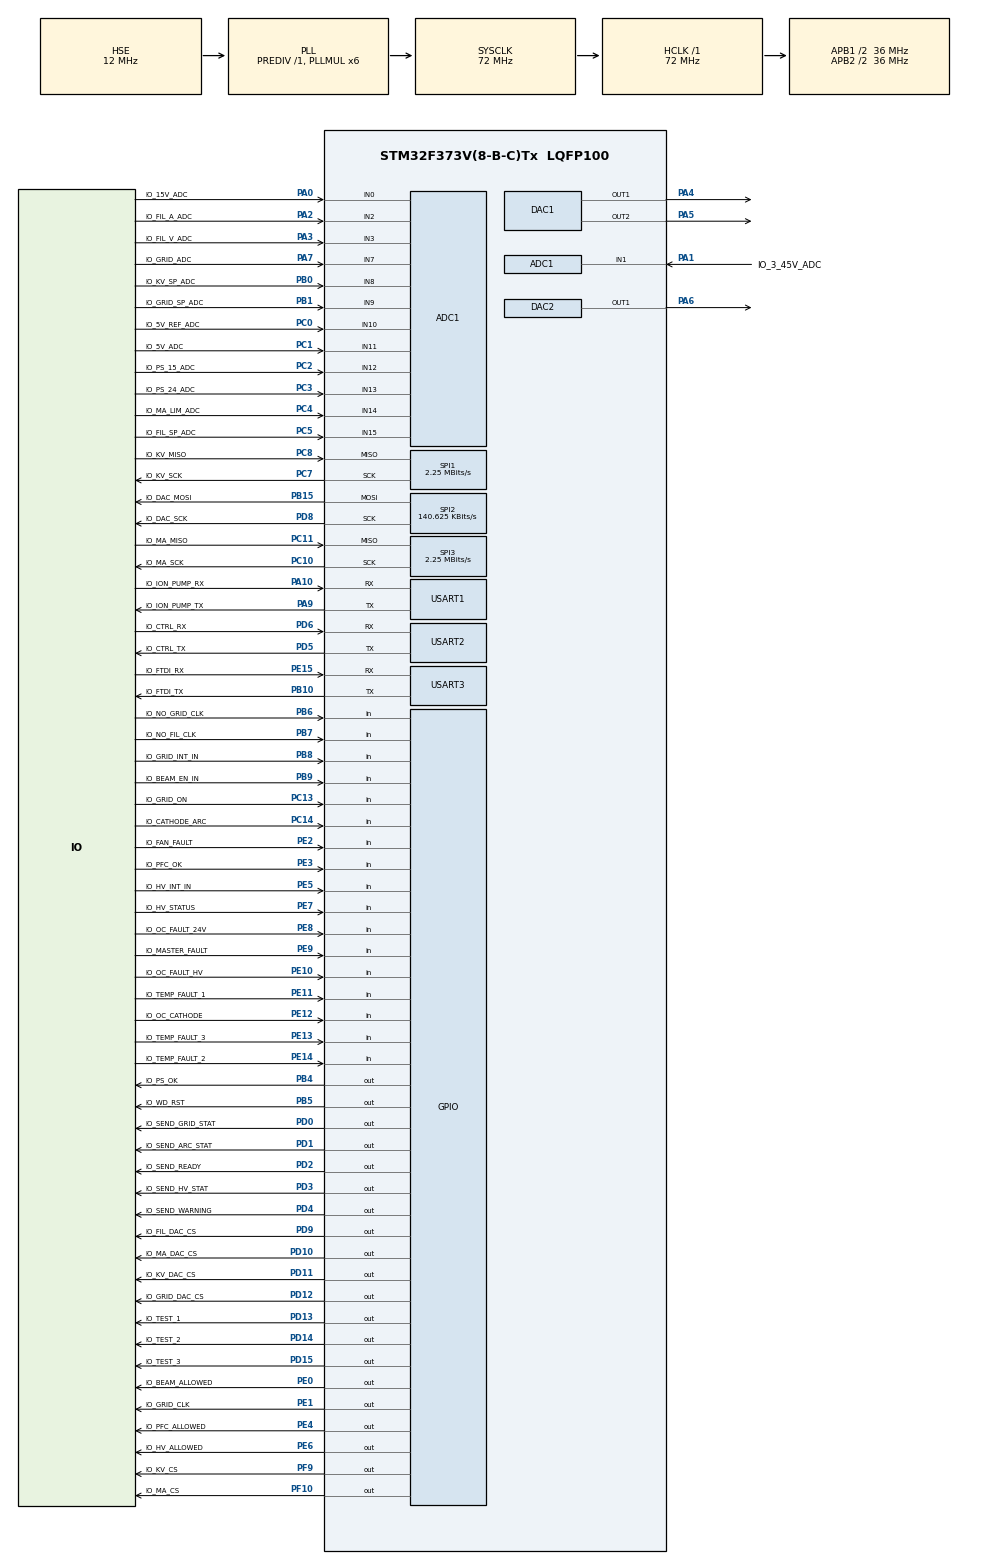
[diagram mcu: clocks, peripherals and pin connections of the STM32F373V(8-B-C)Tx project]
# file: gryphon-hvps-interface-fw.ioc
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ADC1.Channel-1\#ChannelRegularConversion=ADC_CHANNEL_0
ADC1.Channel-10\#ChannelRegularConversion=ADC_CHANNEL_12
ADC1.Channel-11\#ChannelRegularConversion=ADC_CHANNEL_13
ADC1.Channel-12\#ChannelRegularConversion=ADC_CHANNEL_14
ADC1.Channel-13\#ChannelRegularConversion=ADC_CHANNEL_15
ADC1.Channel-14\#ChannelRegularConversion=ADC_CHANNEL_TEMPSENSOR
ADC1.Channel-15\#ChannelRegularConversion=ADC_CHANNEL_VBAT
ADC1.Channel-2\#ChannelRegularConversion=ADC_CHANNEL_1
ADC1.Channel-3\#ChannelRegularConversion=ADC_CHANNEL_2
ADC1.Channel-4\#ChannelRegularConversion=ADC_CHANNEL_3
ADC1.Channel-5\#ChannelRegularConversion=ADC_CHANNEL_7
ADC1.Channel-6\#ChannelRegularConversion=ADC_CHANNEL_8
ADC1.Channel-7\#ChannelRegularConversion=ADC_CHANNEL_9
ADC1.Channel-8\#ChannelRegularConversion=ADC_CHANNEL_10
ADC1.Channel-9\#ChannelRegularConversion=ADC_CHANNEL_11
ADC1.ContinuousConvMode=ENABLE
ADC1.EnableRegularConversion=ENABLE
ADC1.NbrOfConversion=15
ADC1.NbrOfConversionFlag=1
ADC1.Rank-1\#ChannelRegularConversion=1
ADC1.Rank-10\#ChannelRegularConversion=10
ADC1.Rank-11\#ChannelRegularConversion=11
ADC1.Rank-12\#ChannelRegularConversion=12
ADC1.Rank-13\#ChannelRegularConversion=13
ADC1.Rank-14\#ChannelRegularConversion=14
ADC1.Rank-15\#ChannelRegularConversion=15
ADC1.Rank-2\#ChannelRegularConversion=2
ADC1.Rank-3\#ChannelRegularConversion=3
ADC1.Rank-4\#ChannelRegularConversion=4
ADC1.Rank-5\#ChannelRegularConversion=5
ADC1.Rank-6\#ChannelRegularConversion=6
ADC1.Rank-7\#ChannelRegularConversion=7
ADC1.Rank-8\#ChannelRegularConversion=8
ADC1.Rank-9\#ChannelRegularConversion=9
ADC1.SamplingTime-1\#ChannelRegularConversion=ADC_SAMPLETIME_28CYCLES_5
ADC1.SamplingTime-10\#ChannelRegularConversion=ADC_SAMPLETIME_28CYCLES_5
ADC1.SamplingTime-11\#ChannelRegularConversion=ADC_SAMPLETIME_28CYCLES_5
ADC1.SamplingTime-12\#ChannelRegularConversion=ADC_SAMPLETIME_28CYCLES_5
ADC1.SamplingTime-13\#ChannelRegularConversion=ADC_SAMPLETIME_28CYCLES_5
ADC1.SamplingTime-14\#ChannelRegularConversion=ADC_SAMPLETIME_28CYCLES_5
ADC1.SamplingTime-15\#ChannelRegularConversion=ADC_SAMPLETIME_28CYCLES_5
ADC1.SamplingTime-2\#ChannelRegularConversion=ADC_SAMPLETIME_28CYCLES_5
ADC1.SamplingTime-3\#ChannelRegularConversion=ADC_SAMPLETIME_28CYCLES_5
ADC1.SamplingTime-4\#ChannelRegularConversion=ADC_SAMPLETIME_28CYCLES_5
ADC1.SamplingTime-5\#ChannelRegularConversion=ADC_SAMPLETIME_28CYCLES_5
ADC1.SamplingTime-6\#ChannelRegularConversion=ADC_SAMPLETIME_28CYCLES_5
ADC1.SamplingTime-7\#ChannelRegularConversion=ADC_SAMPLETIME_28CYCLES_5
ADC1.SamplingTime-8\#ChannelRegularConversion=ADC_SAMPLETIME_28CYCLES_5
ADC1.SamplingTime-9\#ChannelRegularConversion=ADC_SAMPLETIME_28CYCLES_5
ADC1.master=1
Dma.ADC1.0.Direction=DMA_PERIPH_TO_MEMORY
Dma.ADC1.0.Instance=DMA1_Channel1
Dma.ADC1.0.MemDataAlignment=DMA_MDATAALIGN_HALFWORD
Dma.ADC1.0.MemInc=DMA_MINC_ENABLE
Dma.ADC1.0.Mode=DMA_CIRCULAR
Dma.ADC1.0.PeriphDataAlignment=DMA_PDATAALIGN_HALFWORD
Dma.ADC1.0.PeriphInc=DMA_PINC_DISABLE
Dma.ADC1.0.Priority=DMA_PRIORITY_LOW
Dma.Request0=ADC1
Dma.Request1=SPI1_RX
Dma.Request2=SPI3_RX
Dma.Request3=TIM7_UP
Dma.SPI1_RX.1.Direction=DMA_PERIPH_TO_MEMORY
Dma.SPI1_RX.1.Instance=DMA1_Channel2
Dma.SPI1_RX.1.MemDataAlignment=DMA_MDATAALIGN_BYTE
Dma.SPI1_RX.1.MemInc=DMA_MINC_ENABLE
Dma.SPI1_RX.1.Mode=DMA_NORMAL
Dma.SPI1_RX.1.PeriphDataAlignment=DMA_PDATAALIGN_BYTE
Dma.SPI1_RX.1.PeriphInc=DMA_PINC_DISABLE
Dma.SPI1_RX.1.Priority=DMA_PRIORITY_HIGH
Dma.SPI3_RX.2.Direction=DMA_PERIPH_TO_MEMORY
Dma.SPI3_RX.2.Instance=DMA2_Channel1
Dma.SPI3_RX.2.MemDataAlignment=DMA_MDATAALIGN_BYTE
Dma.SPI3_RX.2.MemInc=DMA_MINC_ENABLE
Dma.SPI3_RX.2.Mode=DMA_NORMAL
Dma.SPI3_RX.2.PeriphDataAlignment=DMA_PDATAALIGN_BYTE
Dma.SPI3_RX.2.PeriphInc=DMA_PINC_DISABLE
Dma.SPI3_RX.2.Priority=DMA_PRIORITY_HIGH
Dma.TIM7_UP.3.Direction=DMA_MEMORY_TO_PERIPH
Dma.TIM7_UP.3.Instance=DMA2_Channel4
Dma.TIM7_UP.3.MemDataAlignment=DMA_MDATAALIGN_WORD
Dma.TIM7_UP.3.MemInc=DMA_MINC_ENABLE
Dma.TIM7_UP.3.Mode=DMA_CIRCULAR
Dma.TIM7_UP.3.PeriphDataAlignment=DMA_PDATAALIGN_WORD
Dma.TIM7_UP.3.PeriphInc=DMA_PINC_DISABLE
Dma.TIM7_UP.3.Priority=DMA_PRIORITY_LOW
FREERTOS.Tasks01=defaultTask,24,128,StartDefaultTask,Default,NULL,Dynamic,NULL,NULL
FREERTOS.configUSE_NEWLIB_REENTRANT=1
FREERTOS.configUSE_TICK_HOOK=1
Mcu.Family=STM32F3
Mcu.Name=STM32F373V(8-B-C)Tx
Mcu.Package=LQFP100
NVIC.DMA1_Channel1_IRQn=true\:5\:0\:false\:false\:true\:true\:false\:true\:true
NVIC.DMA1_Channel2_IRQn=true\:5\:0\:false\:false\:true\:true\:false\:true\:true
NVIC.DMA2_Channel1_IRQn=true\:5\:0\:false\:false\:true\:true\:false\:true\:true
NVIC.DMA2_Channel4_IRQn=true\:5\:0\:false\:false\:true\:true\:false\:true\:true
NVIC.PriorityGroup=NVIC_PRIORITYGROUP_4
NVIC.SPI2_IRQn=true\:5\:0\:false\:false\:true\:true\:true\:true\:true
NVIC.TIM2_IRQn=true\:15\:0\:false\:false\:true\:false\:false\:true\:true
NVIC.TIM6_DAC1_IRQn=true\:5\:0\:false\:false\:true\:true\:true\:true\:true
NVIC.TimeBase=TIM2_IRQn
NVIC.TimeBaseIP=TIM2
NVIC.USART1_IRQn=true\:5\:0\:false\:false\:true\:true\:true\:true\:true
NVIC.USART2_IRQn=true\:5\:0\:false\:false\:true\:true\:true\:true\:true
NVIC.USART3_IRQn=true\:5\:0\:false\:false\:true\:true\:true\:true\:true
PA0.GPIO_Label=IO_15V_ADC
PA0.Mode=IN0
PA0.Signal=ADC1_IN0
PA1.GPIO_Label=IO_3_45V_ADC
PA1.Mode=IN1
PA1.Signal=ADC1_IN1
PA10.GPIO_Label=IO_ION_PUMP_RX
PA10.Mode=Asynchronous
PA10.Signal=USART1_RX
PA13.Mode=Serial_Wire
PA13.Signal=SYS_JTMS-SWDIO
PA14.Mode=Serial_Wire
PA14.Signal=SYS_JTCK-SWCLK
PA2.GPIO_Label=IO_FIL_A_ADC
PA2.Mode=IN2
PA2.Signal=ADC1_IN2
PA3.GPIO_Label=IO_FIL_V_ADC
PA3.Mode=IN3
PA3.Signal=ADC1_IN3
PA4.Signal=COMP_DAC11_group
PA5.Signal=COMP_DAC12_group
PA6.Signal=COMP_DAC21_group
PA7.GPIO_Label=IO_GRID_ADC
PA7.Mode=IN7
PA7.Signal=ADC1_IN7
PA9.GPIO_Label=IO_ION_PUMP_TX
PA9.Mode=Asynchronous
PA9.Signal=USART1_TX
PB0.GPIO_Label=IO_KV_SP_ADC
PB0.Mode=IN8
PB0.Signal=ADC1_IN8
PB1.GPIO_Label=IO_GRID_SP_ADC
PB1.Mode=IN9
PB1.Signal=ADC1_IN9
PB10.GPIO_Label=IO_FTDI_TX
PB10.Mode=Asynchronous
PB10.Signal=USART3_TX
PB15.GPIO_Label=IO_DAC_MOSI
PB15.Mode=TX_Only_Simplex_Unidirect_Master
PB15.Signal=SPI2_MOSI
PB4.GPIO_Label=IO_PS_OK
PB4.Signal=GPIO_Output
PB5.GPIO_Label=IO_WD_RST
PB5.Signal=GPIO_Output
PB6.GPIO_Label=IO_NO_GRID_CLK
PB6.Signal=GPIO_Input
PB7.GPIO_Label=IO_NO_FIL_CLK
PB7.Signal=GPIO_Input
PB8.GPIO_Label=IO_GRID_INT_IN
PB8.Signal=GPIO_Input
PB9.GPIO_Label=IO_BEAM_EN_IN
PB9.Signal=GPIO_Input
PC0.GPIO_Label=IO_5V_REF_ADC
PC0.Mode=IN10
PC0.Signal=ADC1_IN10
PC1.GPIO_Label=IO_5V_ADC
PC1.Mode=IN11
PC1.Signal=ADC1_IN11
PC10.GPIO_Label=IO_MA_SCK
PC10.Mode=RX_Only_Simplex_Unidirect_Master
PC10.Signal=SPI3_SCK
PC11.GPIO_Label=IO_MA_MISO
PC11.Mode=RX_Only_Simplex_Unidirect_Master
PC11.Signal=SPI3_MISO
PC13.GPIO_Label=IO_GRID_ON
PC13.Signal=GPIO_Input
PC14-OSC32_IN.GPIO_Label=IO_CATHODE_ARC
PC14-OSC32_IN.Signal=GPIO_Input
PC2.GPIO_Label=IO_PS_15_ADC
PC2.Mode=IN12
PC2.Signal=ADC1_IN12
PC3.GPIO_Label=IO_PS_24_ADC
PC3.Mode=IN13
PC3.Signal=ADC1_IN13
PC4.GPIO_Label=IO_MA_LIM_ADC
PC4.Mode=IN14
PC4.Signal=ADC1_IN14
PC5.GPIO_Label=IO_FIL_SP_ADC
PC5.Mode=IN15
PC5.Signal=ADC1_IN15
PC7.GPIO_Label=IO_KV_SCK
PC7.Mode=RX_Only_Simplex_Unidirect_Master
PC7.Signal=SPI1_SCK
PC8.GPIO_Label=IO_KV_MISO
PC8.Mode=RX_Only_Simplex_Unidirect_Master
PC8.Signal=SPI1_MISO
PD0.GPIO_Label=IO_SEND_GRID_STAT
PD0.Signal=GPIO_Output
PD1.GPIO_Label=IO_SEND_ARC_STAT
PD1.Signal=GPIO_Output
PD10.GPIO_Label=IO_MA_DAC_CS
PD10.PinState=GPIO_PIN_SET
PD10.Signal=GPIO_Output
PD11.GPIO_Label=IO_KV_DAC_CS
PD11.PinState=GPIO_PIN_SET
PD11.Signal=GPIO_Output
PD12.GPIO_Label=IO_GRID_DAC_CS
PD12.PinState=GPIO_PIN_SET
PD12.Signal=GPIO_Output
PD13.GPIO_Label=IO_TEST_1
PD13.Signal=GPIO_Output
PD14.GPIO_Label=IO_TEST_2
PD14.Signal=GPIO_Output
PD15.GPIO_Label=IO_TEST_3
PD15.Signal=GPIO_Output
PD2.GPIO_Label=IO_SEND_READY
PD2.Signal=GPIO_Output
PD3.GPIO_Label=IO_SEND_HV_STAT
PD3.Signal=GPIO_Output
PD4.GPIO_Label=IO_SEND_WARNING
PD4.Signal=GPIO_Output
PD5.GPIO_Label=IO_CTRL_TX
PD5.Mode=Asynchronous
PD5.Signal=USART2_TX
PD6.GPIO_Label=IO_CTRL_RX
PD6.Mode=Asynchronous
PD6.Signal=USART2_RX
PD8.GPIO_Label=IO_DAC_SCK
PD8.Mode=TX_Only_Simplex_Unidirect_Master
PD8.Signal=SPI2_SCK
PD9.GPIO_Label=IO_FIL_DAC_CS
PD9.PinState=GPIO_PIN_SET
PD9.Signal=GPIO_Output
PE0.GPIO_Label=IO_BEAM_ALLOWED
PE0.Signal=GPIO_Output
PE1.GPIO_Label=IO_GRID_CLK
PE1.Signal=GPIO_Output
PE10.GPIO_Label=IO_OC_FAULT_HV
PE10.Signal=GPIO_Input
PE11.GPIO_Label=IO_TEMP_FAULT_1
PE11.Signal=GPIO_Input
PE12.GPIO_Label=IO_OC_CATHODE
PE12.Signal=GPIO_Input
PE13.GPIO_Label=IO_TEMP_FAULT_3
PE13.Signal=GPIO_Input
PE14.GPIO_Label=IO_TEMP_FAULT_2
PE14.Signal=GPIO_Input
PE15.GPIO_Label=IO_FTDI_RX
PE15.Mode=Asynchronous
PE15.Signal=USART3_RX
PE2.GPIO_Label=IO_FAN_FAULT
PE2.Signal=GPIO_Input
PE3.GPIO_Label=IO_PFC_OK
PE3.Signal=GPIO_Input
PE4.GPIO_Label=IO_PFC_ALLOWED
PE4.Signal=GPIO_Output
PE5.GPIO_Label=IO_HV_INT_IN
PE5.Signal=GPIO_Input
PE6.GPIO_Label=IO_HV_ALLOWED
PE6.Signal=GPIO_Output
PE7.GPIO_Label=IO_HV_STATUS
PE7.Signal=GPIO_Input
PE8.GPIO_Label=IO_OC_FAULT_24V
PE8.Signal=GPIO_Input
PE9.GPIO_Label=IO_MASTER_FAULT
PE9.Signal=GPIO_Input
PF0-OSC_IN.Mode=HSE-External-Oscillator
PF0-OSC_IN.Signal=RCC_OSC_IN
PF1-OSC_OUT.Mode=HSE-External-Oscillator
PF1-OSC_OUT.Signal=RCC_OSC_OUT
PF10.GPIO_Label=IO_MA_CS
PF10.PinState=GPIO_PIN_SET
PF10.Signal=GPIO_Output
PF9.GPIO_Label=IO_KV_CS
PF9.PinState=GPIO_PIN_SET
PF9.Signal=GPIO_Output
ProjectManager.HeapSize=0x200
ProjectManager.StackSize=0x400
ProjectManager.TargetToolchain=STM32CubeIDE
RCC.AHBFreq_Value=72000000
RCC.APB1CLKDivider=RCC_HCLK_DIV2
RCC.APB1Freq_Value=36000000
RCC.APB1TimFreq_Value=72000000
RCC.APB2CLKDivider=RCC_HCLK_DIV2
RCC.APB2Freq_Value=36000000
RCC.APB2TimFreq_Value=72000000
RCC.CortexFreq_Value=72000000
RCC.HCLKFreq_Value=72000000
RCC.HSE_VALUE=12000000
RCC.HSI_VALUE=8000000
RCC.LSE_VALUE=32768
RCC.PLLMUL=RCC_PLL_MUL6
RCC.PLLSourceVirtual=RCC_PLLSOURCE_HSE
RCC.SYSCLKFreq_VALUE=72000000
RCC.SYSCLKSource=RCC_SYSCLKSOURCE_PLLCLK
RCC.USBFreq_Value=72000000
SH.COMP_DAC11_group.0=DAC1_OUT1,DAC_OUT1
SH.COMP_DAC12_group.0=DAC1_OUT2,Enable_DAC_OUT2
SH.COMP_DAC21_group.0=DAC2_OUT1,DAC_OUT1
SPI1.BaudRatePrescaler=SPI_BAUDRATEPRESCALER_16
SPI1.CLKPhase=SPI_PHASE_1EDGE
SPI1.CLKPolarity=SPI_POLARITY_LOW
SPI1.CalculateBaudRate=2.25 MBits/s
SPI1.DataSize=SPI_DATASIZE_8BIT
SPI1.Direction=SPI_DIRECTION_2LINES_RXONLY
SPI1.Mode=SPI_MODE_MASTER
SPI1.NSSPMode=SPI_NSS_PULSE_DISABLE
SPI1.VirtualType=VM_MASTER
SPI2.BaudRatePrescaler=SPI_BAUDRATEPRESCALER_256
SPI2.CLKPhase=SPI_PHASE_2EDGE
SPI2.CalculateBaudRate=140.625 KBits/s
SPI2.DataSize=SPI_DATASIZE_8BIT
SPI2.Direction=SPI_DIRECTION_2LINES
SPI2.Mode=SPI_MODE_MASTER
SPI2.VirtualType=VM_MASTER
SPI3.BaudRatePrescaler=SPI_BAUDRATEPRESCALER_16
SPI3.CalculateBaudRate=2.25 MBits/s
SPI3.DataSize=SPI_DATASIZE_8BIT
SPI3.Direction=SPI_DIRECTION_2LINES_RXONLY
SPI3.Mode=SPI_MODE_MASTER
SPI3.NSSPMode=SPI_NSS_PULSE_DISABLE
SPI3.VirtualType=VM_MASTER
TIM6.Period=9
TIM6.Prescaler=7199
TIM7.Period=7200
USART1.VirtualMode-Asynchronous=VM_ASYNC
USART2.VirtualMode-Asynchronous=VM_ASYNC
USART3.VirtualMode-Asynchronous=VM_ASYNC
VP_ADC1_TempSens_Input.Mode=IN-TempSens
VP_ADC1_Vbat_Input.Mode=IN-Vbat
VP_FREERTOS_VS_CMSIS_V2.Mode=CMSIS_V2
VP_SYS_VS_tim2.Mode=TIM2
VP_TIM6_VS_ClockSourceINT.Mode=Enable_Timer
VP_TIM7_VS_ClockSourceINT.Mode=Enable_Timer
board=custom

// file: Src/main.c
/* USER CODE BEGIN Header */
/**
  ******************************************************************************
  * @file           : main.c
  * @brief          : Main program body
  ******************************************************************************
  * @attention
  *
  * <h2><center>&copy; Copyright (c) 2020 STMicroelectronics.
  * All rights reserved.</center></h2>
  *
  * This software component is licensed by ST under BSD 3-Clause license,
  * the "License"; You may not use this file except in compliance with the
  * License. You may obtain a copy of the License at:
  *                        opensource.org/licenses/BSD-3-Clause
  *
  ******************************************************************************
  */
/* USER CODE END Header */
#include "main.h"
#include "cmsis_os.h"

/* USER CODE BEGIN Includes */
#include "../Sensus Src/setup.h"
#include "../Sensus Src/app_timers.h"
#include "../Sensus Src/ext_adcs.h"
/* USER CODE END Includes */

ADC_HandleTypeDef hadc1;
DMA_HandleTypeDef hdma_adc1;

DAC_HandleTypeDef hdac1;
DAC_HandleTypeDef hdac2;

SPI_HandleTypeDef hspi1;
SPI_HandleTypeDef hspi2;
SPI_HandleTypeDef hspi3;
DMA_HandleTypeDef hdma_spi1_rx;
DMA_HandleTypeDef hdma_spi3_rx;

TIM_HandleTypeDef htim6;
TIM_HandleTypeDef htim7;
DMA_HandleTypeDef hdma_tim7_up;

UART_HandleTypeDef huart1;
UART_HandleTypeDef huart2;
UART_HandleTypeDef huart3;

/* Definitions for defaultTask */
osThreadId_t defaultTaskHandle;
const osThreadAttr_t defaultTask_attributes = {
  .name = "defaultTask",
  .stack_size = 128 * 8,
  .priority = (osPriority_t) osPriorityNormal,
};

void SystemClock_Config(void);
static void MX_GPIO_Init(void);
static void MX_DMA_Init(void);
static void MX_ADC1_Init(void);
static void MX_DAC1_Init(void);
static void MX_DAC2_Init(void);
static void MX_SPI1_Init(void);
static void MX_SPI2_Init(void);
static void MX_SPI3_Init(void);
static void MX_USART1_UART_Init(void);
static void MX_USART2_UART_Init(void);
static void MX_USART3_UART_Init(void);
static void MX_TIM7_Init(void);
static void MX_TIM6_Init(void);
void StartDefaultTask(void *argument);

int main(void)
{

  /* USER CODE BEGIN 1 */
  /* SystemInit configures SCB->VTOR for the MCUboot application address. */
  /* USER CODE END 1 */

  /* MCU Configuration--------------------------------------------------------*/

  /* Reset of all peripherals, Initializes the Flash interface and the Systick. */
  HAL_Init();

  /* Configure the system clock */
  SystemClock_Config();

  /* Initialize all configured peripherals */
  MX_GPIO_Init();
  MX_DMA_Init();
  MX_ADC1_Init();
  MX_DAC1_Init();
  MX_DAC2_Init();
  MX_SPI1_Init();
  MX_SPI2_Init();
  MX_SPI3_Init();
  MX_USART1_UART_Init();
  MX_USART2_UART_Init();
  MX_USART3_UART_Init();
  MX_TIM7_Init();
  MX_TIM6_Init();

  /* Init scheduler */
  osKernelInitialize();

  /* Create the thread(s) */
  /* creation of defaultTask */
  defaultTaskHandle = osThreadNew(StartDefaultTask, NULL, &defaultTask_attributes);

  /* Start scheduler */
  osKernelStart();

  /* We should never get here as control is now taken by the scheduler */

  /* Infinite loop */
  while (1)
  {

  }
}

void SystemClock_Config(void)
{
  RCC_OscInitTypeDef RCC_OscInitStruct = {0};
  RCC_ClkInitTypeDef RCC_ClkInitStruct = {0};
  RCC_PeriphCLKInitTypeDef PeriphClkInit = {0};

  /** Initializes the RCC Oscillators according to the specified parameters
  * in the RCC_OscInitTypeDef structure.
  */
  RCC_OscInitStruct.OscillatorType = RCC_OSCILLATORTYPE_HSE;
  RCC_OscInitStruct.HSEState = RCC_HSE_ON;
  RCC_OscInitStruct.HSEPredivValue = RCC_HSE_PREDIV_DIV1;
  RCC_OscInitStruct.HSIState = RCC_HSI_ON;
  RCC_OscInitStruct.PLL.PLLState = RCC_PLL_ON;
  RCC_OscInitStruct.PLL.PLLSource = RCC_PLLSOURCE_HSE;
  RCC_OscInitStruct.PLL.PLLMUL = RCC_PLL_MUL6;
  if (HAL_RCC_OscConfig(&RCC_OscInitStruct) != HAL_OK)
  {
    Error_Handler();
  }

  /** Initializes the CPU, AHB and APB buses clocks
  */
  RCC_ClkInitStruct.ClockType = RCC_CLOCKTYPE_HCLK|RCC_CLOCKTYPE_SYSCLK
                              |RCC_CLOCKTYPE_PCLK1|RCC_CLOCKTYPE_PCLK2;
  RCC_ClkInitStruct.SYSCLKSource = RCC_SYSCLKSOURCE_PLLCLK;
  RCC_ClkInitStruct.AHBCLKDivider = RCC_SYSCLK_DIV1;
  RCC_ClkInitStruct.APB1CLKDivider = RCC_HCLK_DIV2;
  RCC_ClkInitStruct.APB2CLKDivider = RCC_HCLK_DIV2;

  if (HAL_RCC_ClockConfig(&RCC_ClkInitStruct, FLASH_LATENCY_2) != HAL_OK)
  {
    Error_Handler();
  }
  PeriphClkInit.PeriphClockSelection = RCC_PERIPHCLK_USART1|RCC_PERIPHCLK_USART2
                              |RCC_PERIPHCLK_USART3|RCC_PERIPHCLK_ADC1;
  PeriphClkInit.Usart1ClockSelection = RCC_USART1CLKSOURCE_PCLK2;
  PeriphClkInit.Usart2ClockSelection = RCC_USART2CLKSOURCE_PCLK1;
  PeriphClkInit.Usart3ClockSelection = RCC_USART3CLKSOURCE_PCLK1;
  PeriphClkInit.Adc1ClockSelection = RCC_ADC1PCLK2_DIV2;

  if (HAL_RCCEx_PeriphCLKConfig(&PeriphClkInit) != HAL_OK)
  {
    Error_Handler();
  }
}

static void MX_ADC1_Init(void)
{

  ADC_ChannelConfTypeDef sConfig = {0};

  /** Common config
  */
  hadc1.Instance = ADC1;
  hadc1.Init.ScanConvMode = ADC_SCAN_ENABLE;
  hadc1.Init.ContinuousConvMode = ENABLE;
  hadc1.Init.DiscontinuousConvMode = DISABLE;
  hadc1.Init.ExternalTrigConv = ADC_SOFTWARE_START;
  hadc1.Init.DataAlign = ADC_DATAALIGN_RIGHT;
  hadc1.Init.NbrOfConversion = 15;
  if (HAL_ADC_Init(&hadc1) != HAL_OK)
  {
    Error_Handler();
  }

  /** Configure Regular Channel
  */
  sConfig.Channel = ADC_CHANNEL_0;
  sConfig.Rank = ADC_REGULAR_RANK_1;
  sConfig.SamplingTime = ADC_SAMPLETIME_28CYCLES_5;
  if (HAL_ADC_ConfigChannel(&hadc1, &sConfig) != HAL_OK)
  {
    Error_Handler();
  }

  /** Configure Regular Channel
  */
  sConfig.Channel = ADC_CHANNEL_1;
  sConfig.Rank = ADC_REGULAR_RANK_2;
  if (HAL_ADC_ConfigChannel(&hadc1, &sConfig) != HAL_OK)
  {
    Error_Handler();
  }

  /** Configure Regular Channel
  */
  sConfig.Channel = ADC_CHANNEL_2;
  sConfig.Rank = ADC_REGULAR_RANK_3;
  if (HAL_ADC_ConfigChannel(&hadc1, &sConfig) != HAL_OK)
  {
    Error_Handler();
  }

  /** Configure Regular Channel
  */
  sConfig.Channel = ADC_CHANNEL_3;
  sConfig.Rank = ADC_REGULAR_RANK_4;
  if (HAL_ADC_ConfigChannel(&hadc1, &sConfig) != HAL_OK)
  {
    Error_Handler();
  }

  /** Configure Regular Channel
  */
  sConfig.Channel = ADC_CHANNEL_7;
  sConfig.Rank = ADC_REGULAR_RANK_5;
  if (HAL_ADC_ConfigChannel(&hadc1, &sConfig) != HAL_OK)
  {
    Error_Handler();
  }

  /** Configure Regular Channel
  */
  sConfig.Channel = ADC_CHANNEL_8;
  sConfig.Rank = ADC_REGULAR_RANK_6;
  if (HAL_ADC_ConfigChannel(&hadc1, &sConfig) != HAL_OK)
  {
    Error_Handler();
  }

  /** Configure Regular Channel
  */
  sConfig.Channel = ADC_CHANNEL_9;
  sConfig.Rank = ADC_REGULAR_RANK_7;
  if (HAL_ADC_ConfigChannel(&hadc1, &sConfig) != HAL_OK)
  {
    Error_Handler();
  }

  /** Configure Regular Channel
  */
  sConfig.Channel = ADC_CHANNEL_10;
  sConfig.Rank = ADC_REGULAR_RANK_8;
  if (HAL_ADC_ConfigChannel(&hadc1, &sConfig) != HAL_OK)
  {
    Error_Handler();
  }

  /** Configure Regular Channel
  */
  sConfig.Channel = ADC_CHANNEL_11;
  sConfig.Rank = ADC_REGULAR_RANK_9;
  if (HAL_ADC_ConfigChannel(&hadc1, &sConfig) != HAL_OK)
  {
    Error_Handler();
  }

  /** Configure Regular Channel
  */
  sConfig.Channel = ADC_CHANNEL_12;
  sConfig.Rank = ADC_REGULAR_RANK_10;
  if (HAL_ADC_ConfigChannel(&hadc1, &sConfig) != HAL_OK)
  {
    Error_Handler();
  }

  /** Configure Regular Channel
  */
  sConfig.Channel = ADC_CHANNEL_13;
  sConfig.Rank = ADC_REGULAR_RANK_11;
  if (HAL_ADC_ConfigChannel(&hadc1, &sConfig) != HAL_OK)
  {
    Error_Handler();
  }

  /** Configure Regular Channel
  */
  sConfig.Channel = ADC_CHANNEL_14;
  sConfig.Rank = ADC_REGULAR_RANK_12;
  if (HAL_ADC_ConfigChannel(&hadc1, &sConfig) != HAL_OK)
  {
    Error_Handler();
  }

  /** Configure Regular Channel
  */
  sConfig.Channel = ADC_CHANNEL_15;
  sConfig.Rank = ADC_REGULAR_RANK_13;
  if (HAL_ADC_ConfigChannel(&hadc1, &sConfig) != HAL_OK)
  {
    Error_Handler();
  }

  /** Configure Regular Channel
  */
  sConfig.Channel = ADC_CHANNEL_TEMPSENSOR;
  sConfig.Rank = ADC_REGULAR_RANK_14;
  if (HAL_ADC_ConfigChannel(&hadc1, &sConfig) != HAL_OK)
  {
    Error_Handler();
  }

  /** Configure Regular Channel
  */
  sConfig.Channel = ADC_CHANNEL_VBAT;
  sConfig.Rank = ADC_REGULAR_RANK_15;
  if (HAL_ADC_ConfigChannel(&hadc1, &sConfig) != HAL_OK)
  {
    Error_Handler();
  }

}

static void MX_DAC1_Init(void)
{

  DAC_ChannelConfTypeDef sConfig = {0};

  /** DAC Initialization
  */
  hdac1.Instance = DAC1;
  if (HAL_DAC_Init(&hdac1) != HAL_OK)
  {
    Error_Handler();
  }

  /** DAC channel OUT1 config
  */
  sConfig.DAC_Trigger = DAC_TRIGGER_NONE;
  sConfig.DAC_OutputBuffer = DAC_OUTPUTBUFFER_ENABLE;
  if (HAL_DAC_ConfigChannel(&hdac1, &sConfig, DAC_CHANNEL_1) != HAL_OK)
  {
    Error_Handler();
  }

  /** DAC channel OUT2 config
  */
  if (HAL_DAC_ConfigChannel(&hdac1, &sConfig, DAC_CHANNEL_2) != HAL_OK)
  {
    Error_Handler();
  }

}

static void MX_DAC2_Init(void)
{

  DAC_ChannelConfTypeDef sConfig = {0};

  /** DAC Initialization
  */
  hdac2.Instance = DAC2;
  if (HAL_DAC_Init(&hdac2) != HAL_OK)
  {
    Error_Handler();
  }

  /** DAC channel OUT1 config
  */
  sConfig.DAC_Trigger = DAC_TRIGGER_NONE;
  sConfig.DAC_OutputBuffer = DAC_OUTPUTBUFFER_ENABLE;
  if (HAL_DAC_ConfigChannel(&hdac2, &sConfig, DAC_CHANNEL_1) != HAL_OK)
  {
    Error_Handler();
  }

}

static void MX_SPI1_Init(void)
{

  /* SPI1 parameter configuration*/
  hspi1.Instance = SPI1;
  hspi1.Init.Mode = SPI_MODE_MASTER;
  hspi1.Init.Direction = SPI_DIRECTION_2LINES_RXONLY;
  hspi1.Init.DataSize = SPI_DATASIZE_8BIT;
  hspi1.Init.CLKPolarity = SPI_POLARITY_LOW;
  hspi1.Init.CLKPhase = SPI_PHASE_1EDGE;
  hspi1.Init.NSS = SPI_NSS_SOFT;
  hspi1.Init.BaudRatePrescaler = SPI_BAUDRATEPRESCALER_16;
  hspi1.Init.FirstBit = SPI_FIRSTBIT_MSB;
  hspi1.Init.TIMode = SPI_TIMODE_DISABLE;
  hspi1.Init.CRCCalculation = SPI_CRCCALCULATION_DISABLE;
  hspi1.Init.CRCPolynomial = 7;
  hspi1.Init.CRCLength = SPI_CRC_LENGTH_DATASIZE;
  hspi1.Init.NSSPMode = SPI_NSS_PULSE_DISABLE;
  if (HAL_SPI_Init(&hspi1) != HAL_OK)
  {
    Error_Handler();
  }

}

static void MX_SPI2_Init(void)
{

  /* SPI2 parameter configuration*/
  hspi2.Instance = SPI2;
  hspi2.Init.Mode = SPI_MODE_MASTER;
  hspi2.Init.Direction = SPI_DIRECTION_2LINES;
  hspi2.Init.DataSize = SPI_DATASIZE_8BIT;
  hspi2.Init.CLKPolarity = SPI_POLARITY_LOW;
  hspi2.Init.CLKPhase = SPI_PHASE_2EDGE;
  hspi2.Init.NSS = SPI_NSS_SOFT;
  hspi2.Init.BaudRatePrescaler = SPI_BAUDRATEPRESCALER_256;
  hspi2.Init.FirstBit = SPI_FIRSTBIT_MSB;
  hspi2.Init.TIMode = SPI_TIMODE_DISABLE;
  hspi2.Init.CRCCalculation = SPI_CRCCALCULATION_DISABLE;
  hspi2.Init.CRCPolynomial = 7;
  hspi2.Init.CRCLength = SPI_CRC_LENGTH_DATASIZE;
  hspi2.Init.NSSPMode = SPI_NSS_PULSE_DISABLE;
  if (HAL_SPI_Init(&hspi2) != HAL_OK)
  {
    Error_Handler();
  }

}

static void MX_SPI3_Init(void)
{

  /* SPI3 parameter configuration*/
  hspi3.Instance = SPI3;
  hspi3.Init.Mode = SPI_MODE_MASTER;
  hspi3.Init.Direction = SPI_DIRECTION_2LINES_RXONLY;
  hspi3.Init.DataSize = SPI_DATASIZE_8BIT;
  hspi3.Init.CLKPolarity = SPI_POLARITY_LOW;
  hspi3.Init.CLKPhase = SPI_PHASE_1EDGE;
  hspi3.Init.NSS = SPI_NSS_SOFT;
  hspi3.Init.BaudRatePrescaler = SPI_BAUDRATEPRESCALER_16;
  hspi3.Init.FirstBit = SPI_FIRSTBIT_MSB;
  hspi3.Init.TIMode = SPI_TIMODE_DISABLE;
  hspi3.Init.CRCCalculation = SPI_CRCCALCULATION_DISABLE;
  hspi3.Init.CRCPolynomial = 7;
  hspi3.Init.CRCLength = SPI_CRC_LENGTH_DATASIZE;
  hspi3.Init.NSSPMode = SPI_NSS_PULSE_DISABLE;
  if (HAL_SPI_Init(&hspi3) != HAL_OK)
  {
    Error_Handler();
  }

}

static void MX_TIM6_Init(void)
{

  TIM_MasterConfigTypeDef sMasterConfig = {0};

  htim6.Instance = TIM6;
  htim6.Init.Prescaler = 7199;
  htim6.Init.CounterMode = TIM_COUNTERMODE_UP;
  htim6.Init.Period = 9;
  htim6.Init.AutoReloadPreload = TIM_AUTORELOAD_PRELOAD_DISABLE;
  if (HAL_TIM_Base_Init(&htim6) != HAL_OK)
  {
    Error_Handler();
  }
  sMasterConfig.MasterOutputTrigger = TIM_TRGO_RESET;
  sMasterConfig.MasterSlaveMode = TIM_MASTERSLAVEMODE_DISABLE;
  if (HAL_TIMEx_MasterConfigSynchronization(&htim6, &sMasterConfig) != HAL_OK)
  {
    Error_Handler();
  }

}

static void MX_TIM7_Init(void)
{

  TIM_MasterConfigTypeDef sMasterConfig = {0};

  htim7.Instance = TIM7;
  htim7.Init.Prescaler = 0;
  htim7.Init.CounterMode = TIM_COUNTERMODE_UP;
  htim7.Init.Period = 7200;
  htim7.Init.AutoReloadPreload = TIM_AUTORELOAD_PRELOAD_DISABLE;
  if (HAL_TIM_Base_Init(&htim7) != HAL_OK)
  {
    Error_Handler();
  }
  sMasterConfig.MasterOutputTrigger = TIM_TRGO_RESET;
  sMasterConfig.MasterSlaveMode = TIM_MASTERSLAVEMODE_DISABLE;
  if (HAL_TIMEx_MasterConfigSynchronization(&htim7, &sMasterConfig) != HAL_OK)
  {
    Error_Handler();
  }

}

static void MX_USART1_UART_Init(void)
{

  huart1.Instance = USART1;
  huart1.Init.BaudRate = 38400;
  huart1.Init.WordLength = UART_WORDLENGTH_8B;
  huart1.Init.StopBits = UART_STOPBITS_1;
  huart1.Init.Parity = UART_PARITY_NONE;
  huart1.Init.Mode = UART_MODE_TX_RX;
  huart1.Init.HwFlowCtl = UART_HWCONTROL_NONE;
  huart1.Init.OverSampling = UART_OVERSAMPLING_16;
  huart1.Init.OneBitSampling = UART_ONE_BIT_SAMPLE_DISABLE;
  huart1.AdvancedInit.AdvFeatureInit = UART_ADVFEATURE_NO_INIT;
  if (HAL_UART_Init(&huart1) != HAL_OK)
  {
    Error_Handler();
  }

}

static void MX_USART2_UART_Init(void)
{

  huart2.Instance = USART2;
  huart2.Init.BaudRate = 38400;
  huart2.Init.WordLength = UART_WORDLENGTH_8B;
  huart2.Init.StopBits = UART_STOPBITS_1;
  huart2.Init.Parity = UART_PARITY_NONE;
  huart2.Init.Mode = UART_MODE_TX_RX;
  huart2.Init.HwFlowCtl = UART_HWCONTROL_NONE;
  huart2.Init.OverSampling = UART_OVERSAMPLING_16;
  huart2.Init.OneBitSampling = UART_ONE_BIT_SAMPLE_DISABLE;
  huart2.AdvancedInit.AdvFeatureInit = UART_ADVFEATURE_NO_INIT;
  if (HAL_UART_Init(&huart2) != HAL_OK)
  {
    Error_Handler();
  }

}

static void MX_USART3_UART_Init(void)
{

  huart3.Instance = USART3;
  huart3.Init.BaudRate = 38400;
  huart3.Init.WordLength = UART_WORDLENGTH_8B;
  huart3.Init.StopBits = UART_STOPBITS_1;
  huart3.Init.Parity = UART_PARITY_NONE;
  huart3.Init.Mode = UART_MODE_TX_RX;
  huart3.Init.HwFlowCtl = UART_HWCONTROL_NONE;
  huart3.Init.OverSampling = UART_OVERSAMPLING_16;
  huart3.Init.OneBitSampling = UART_ONE_BIT_SAMPLE_DISABLE;
  huart3.AdvancedInit.AdvFeatureInit = UART_ADVFEATURE_NO_INIT;
  if (HAL_UART_Init(&huart3) != HAL_OK)
  {
    Error_Handler();
  }

}

static void MX_DMA_Init(void)
{

  /* DMA controller clock enable */
  __HAL_RCC_DMA1_CLK_ENABLE();
  __HAL_RCC_DMA2_CLK_ENABLE();

  /* DMA interrupt init */
  /* DMA1_Channel1_IRQn interrupt configuration */
  HAL_NVIC_SetPriority(DMA1_Channel1_IRQn, 5, 0);
  HAL_NVIC_EnableIRQ(DMA1_Channel1_IRQn);
  /* DMA1_Channel2_IRQn interrupt configuration */
  HAL_NVIC_SetPriority(DMA1_Channel2_IRQn, 5, 0);
  HAL_NVIC_EnableIRQ(DMA1_Channel2_IRQn);
  /* DMA2_Channel1_IRQn interrupt configuration */
  HAL_NVIC_SetPriority(DMA2_Channel1_IRQn, 5, 0);
  HAL_NVIC_EnableIRQ(DMA2_Channel1_IRQn);
  /* DMA2_Channel4_IRQn interrupt configuration */
  HAL_NVIC_SetPriority(DMA2_Channel4_IRQn, 5, 0);
  HAL_NVIC_EnableIRQ(DMA2_Channel4_IRQn);

}

static void MX_GPIO_Init(void)
{
  GPIO_InitTypeDef GPIO_InitStruct = {0};

  /* GPIO Ports Clock Enable */
  __HAL_RCC_GPIOE_CLK_ENABLE();
  __HAL_RCC_GPIOC_CLK_ENABLE();
  __HAL_RCC_GPIOF_CLK_ENABLE();
  __HAL_RCC_GPIOA_CLK_ENABLE();
  __HAL_RCC_GPIOB_CLK_ENABLE();
  __HAL_RCC_GPIOD_CLK_ENABLE();

  /*Configure GPIO pin Output Level */
  HAL_GPIO_WritePin(GPIOE, IO_PFC_ALLOWED_Pin|IO_HV_ALLOWED_Pin|IO_BEAM_ALLOWED_Pin|IO_GRID_CLK_Pin, GPIO_PIN_RESET);

  /*Configure GPIO pin Output Level */
  HAL_GPIO_WritePin(GPIOF, IO_KV_CS_Pin|IO_MA_CS_Pin, GPIO_PIN_SET);

  /*Configure GPIO pin Output Level */
  HAL_GPIO_WritePin(GPIOD, IO_FIL_DAC_CS_Pin|IO_MA_DAC_CS_Pin|IO_KV_DAC_CS_Pin|IO_GRID_DAC_CS_Pin, GPIO_PIN_SET);

  /*Configure GPIO pin Output Level */
  HAL_GPIO_WritePin(GPIOD, IO_TEST_1_Pin|IO_TEST_2_Pin|IO_TEST_3_Pin|IO_SEND_GRID_STAT_Pin
                          |IO_SEND_ARC_STAT_Pin|IO_SEND_READY_Pin|IO_SEND_HV_STAT_Pin|IO_SEND_WARNING_Pin, GPIO_PIN_RESET);

  /*Configure GPIO pin Output Level */
  HAL_GPIO_WritePin(GPIOB, IO_PS_OK_Pin|IO_WD_RST_Pin, GPIO_PIN_RESET);

  /*Configure GPIO pins : IO_FAN_FAULT_Pin IO_PFC_OK_Pin IO_HV_INT_IN_Pin IO_HV_STATUS_Pin
                           IO_OC_FAULT_24V_Pin IO_MASTER_FAULT_Pin IO_OC_FAULT_HV_Pin IO_TEMP_FAULT_1_Pin
                           IO_OC_CATHODE_Pin IO_TEMP_FAULT_3_Pin IO_TEMP_FAULT_2_Pin */
  GPIO_InitStruct.Pin = IO_FAN_FAULT_Pin|IO_PFC_OK_Pin|IO_HV_INT_IN_Pin|IO_HV_STATUS_Pin
                          |IO_OC_FAULT_24V_Pin|IO_MASTER_FAULT_Pin|IO_OC_FAULT_HV_Pin|IO_TEMP_FAULT_1_Pin
                          |IO_OC_CATHODE_Pin|IO_TEMP_FAULT_3_Pin|IO_TEMP_FAULT_2_Pin;
  GPIO_InitStruct.Mode = GPIO_MODE_INPUT;
  GPIO_InitStruct.Pull = GPIO_NOPULL;
  HAL_GPIO_Init(GPIOE, &GPIO_InitStruct);

  /*Configure GPIO pins : IO_PFC_ALLOWED_Pin IO_HV_ALLOWED_Pin IO_BEAM_ALLOWED_Pin IO_GRID_CLK_Pin */
  GPIO_InitStruct.Pin = IO_PFC_ALLOWED_Pin|IO_HV_ALLOWED_Pin|IO_BEAM_ALLOWED_Pin|IO_GRID_CLK_Pin;
  GPIO_InitStruct.Mode = GPIO_MODE_OUTPUT_PP;
  GPIO_InitStruct.Pull = GPIO_NOPULL;
  GPIO_InitStruct.Speed = GPIO_SPEED_FREQ_LOW;
  HAL_GPIO_Init(GPIOE, &GPIO_InitStruct);

  /*Configure GPIO pins : IO_GRID_ON_Pin IO_CATHODE_ARC_Pin */
  GPIO_InitStruct.Pin = IO_GRID_ON_Pin|IO_CATHODE_ARC_Pin;
  GPIO_InitStruct.Mode = GPIO_MODE_INPUT;
  GPIO_InitStruct.Pull = GPIO_NOPULL;
  HAL_GPIO_Init(GPIOC, &GPIO_InitStruct);

  /*Configure GPIO pins : IO_KV_CS_Pin IO_MA_CS_Pin */
  GPIO_InitStruct.Pin = IO_KV_CS_Pin|IO_MA_CS_Pin;
  GPIO_InitStruct.Mode = GPIO_MODE_OUTPUT_PP;
  GPIO_InitStruct.Pull = GPIO_NOPULL;
  GPIO_InitStruct.Speed = GPIO_SPEED_FREQ_LOW;
  HAL_GPIO_Init(GPIOF, &GPIO_InitStruct);

  /*Configure GPIO pins : IO_FIL_DAC_CS_Pin IO_MA_DAC_CS_Pin IO_KV_DAC_CS_Pin IO_GRID_DAC_CS_Pin
                           IO_TEST_1_Pin IO_TEST_2_Pin IO_TEST_3_Pin IO_SEND_GRID_STAT_Pin
                           IO_SEND_ARC_STAT_Pin IO_SEND_READY_Pin IO_SEND_HV_STAT_Pin IO_SEND_WARNING_Pin */
  GPIO_InitStruct.Pin = IO_FIL_DAC_CS_Pin|IO_MA_DAC_CS_Pin|IO_KV_DAC_CS_Pin|IO_GRID_DAC_CS_Pin
                          |IO_TEST_1_Pin|IO_TEST_2_Pin|IO_TEST_3_Pin|IO_SEND_GRID_STAT_Pin
                          |IO_SEND_ARC_STAT_Pin|IO_SEND_READY_Pin|IO_SEND_HV_STAT_Pin|IO_SEND_WARNING_Pin;
  GPIO_InitStruct.Mode = GPIO_MODE_OUTPUT_PP;
  GPIO_InitStruct.Pull = GPIO_NOPULL;
  GPIO_InitStruct.Speed = GPIO_SPEED_FREQ_LOW;
  HAL_GPIO_Init(GPIOD, &GPIO_InitStruct);

  /*Configure GPIO pins : IO_PS_OK_Pin IO_WD_RST_Pin */
  GPIO_InitStruct.Pin = IO_PS_OK_Pin|IO_WD_RST_Pin;
  GPIO_InitStruct.Mode = GPIO_MODE_OUTPUT_PP;
  GPIO_InitStruct.Pull = GPIO_NOPULL;
  GPIO_InitStruct.Speed = GPIO_SPEED_FREQ_LOW;
  HAL_GPIO_Init(GPIOB, &GPIO_InitStruct);

  /*Configure GPIO pins : IO_NO_GRID_CLK_Pin IO_NO_FIL_CLK_Pin IO_GRID_INT_IN_Pin IO_BEAM_EN_IN_Pin */
  GPIO_InitStruct.Pin = IO_NO_GRID_CLK_Pin|IO_NO_FIL_CLK_Pin|IO_GRID_INT_IN_Pin|IO_BEAM_EN_IN_Pin;
  GPIO_InitStruct.Mode = GPIO_MODE_INPUT;
  GPIO_InitStruct.Pull = GPIO_NOPULL;
  HAL_GPIO_Init(GPIOB, &GPIO_InitStruct);

}

void StartDefaultTask(void *argument)
{
  /* USER CODE BEGIN 5 */
  run_setup();
  /* Infinite loop */
  for(;;)
  {
    run_loop();
  }
  /* USER CODE END 5 */
}

void HAL_TIM_PeriodElapsedCallback(TIM_HandleTypeDef *htim)
{
  if (htim->Instance == TIM2)
  {
    HAL_IncTick();
  }
  /* USER CODE BEGIN Callback 1 */
	else if(htim->Instance == TIM6)
	{
		static uint8_t adc_period_ms = 0U;
		if (adc_period_ms == 0U)
		{
			ext_adcs_start_burst_from_isr();
		}
		else if (adc_period_ms == 2U)
		{
			ext_adcs_check_completion_from_isr();
		}

		adc_period_ms++;
		if (adc_period_ms == 5U)
		{
			adc_period_ms = 0U;
		}
		runtime_ms++;
	}
  /* USER CODE END Callback 1 */
}

void Error_Handler(void)
{
}

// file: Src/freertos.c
/* USER CODE BEGIN Header */
/**
  ******************************************************************************
  * File Name          : freertos.c
  * Description        : Code for freertos applications
  ******************************************************************************
  * @attention
  *
  * Copyright (c) 2026 STMicroelectronics.
  * All rights reserved.
  *
  * This software is licensed under terms that can be found in the LICENSE file
  * in the root directory of this software component.
  * If no LICENSE file comes with this software, it is provided AS-IS.
  *
  ******************************************************************************
  */
/* USER CODE END Header */

#include "FreeRTOS.h"
#include "task.h"
#include "main.h"

/* USER CODE BEGIN Includes */
#include "timers.h"
#include "../Sensus Src/app_timers.h"
/* USER CODE END Includes */

/* Hook prototypes */
void vApplicationTickHook(void);

/* USER CODE BEGIN 3 */
void vApplicationTickHook( void )
{
    update_timers();
}
/* USER CODE END 3 */
